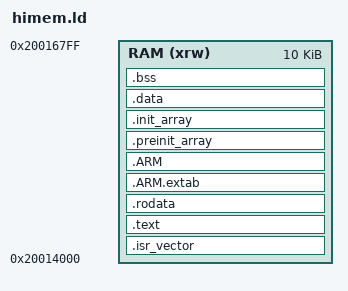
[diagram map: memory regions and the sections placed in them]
ENTRY(Reset_Handler)

/* Highest address of the user mode stack */ 
_estack = 0x20016800;    /* end of RAM */

/* Specify the memory areas */
MEMORY
{
    RAM (xrw)      : ORIGIN = 0x20014000, LENGTH = 10K
}

/* Define output sections */
SECTIONS
{
  .isr_vector :
  {
    . = ALIGN(4);
    KEEP(*(.isr_vector)) /* Startup code */
    . = ALIGN(4);
  } >RAM

  .text :
  {
    . = ALIGN(4);
    *(.text)           /* .text sections (code) */
    *(.text*)          /* .text* sections (code) */
    *(.glue_7)         /* glue arm to thumb code */
    *(.glue_7t)        /* glue thumb to arm code */
    *(.eh_frame)

    KEEP (*(.init))

    . = ALIGN(4);
    _etext = .;        /* define a global symbols at end of code */
  } >RAM

  .rodata :
  {
    . = ALIGN(4);
    *(.rodata)         /* .rodata sections (constants, strings, etc.) */
    *(.rodata*)        /* .rodata* sections (constants, strings, etc.) */
    . = ALIGN(4);
  } >RAM

  .ARM.extab   : { *(.ARM.extab* .gnu.linkonce.armextab.*) } >RAM
  .ARM : {
    __exidx_start = .;
    *(.ARM.exidx*)
    __exidx_end = .;
  } >RAM

  .preinit_array     :
  {
    PROVIDE_HIDDEN (__preinit_array_start = .);
    KEEP (*(.preinit_array*))
    PROVIDE_HIDDEN (__preinit_array_end = .);
  } >RAM
  .init_array :
  {
    PROVIDE_HIDDEN (__init_array_start = .);
    KEEP (*(SORT(.init_array.*)))
    KEEP (*(.init_array*))
    PROVIDE_HIDDEN (__init_array_end = .);
  } >RAM

  /* Initialized data sections goes into RAM, load LMA copy after code */
  .data : 
  {
    . = ALIGN(4);
    _sdata = .;        /* create a global symbol at data start */
    *(.data)           /* .data sections */
    *(.data*)          /* .data* sections */

    . = ALIGN(4);
    _edata = .;        /* define a global symbol at data end */
  } >RAM
  
  /* Uninitialized data section */
  . = ALIGN(4);
  .bss :
  {
    /* This is used by the startup in order to initialize the .bss secion */
    _sbss = .;         /* define a global symbol at bss start */
    __bss_start__ = _sbss;
    *(.bss)
    *(.bss*)
    *(COMMON)

    . = ALIGN(4);
    _ebss = .;         /* define a global symbol at bss end */
    __bss_end__ = _ebss;
  } >RAM

  /* Remove information from the standard libraries */
  /DISCARD/ :
  {
    libc.a ( * )
    libm.a ( * )
    libgcc.a ( * )
  }

  .ARM.attributes 0 : { *(.ARM.attributes) }
}


